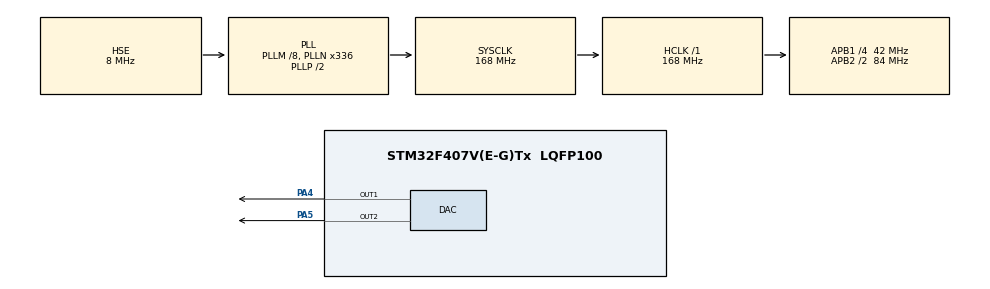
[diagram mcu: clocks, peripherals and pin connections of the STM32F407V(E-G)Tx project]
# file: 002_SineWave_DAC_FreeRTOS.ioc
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DAC.DAC_Trigger=DAC_TRIGGER_T6_TRGO
DAC.DAC_Trigger2=DAC_TRIGGER_T6_TRGO
Dma.DAC1.0.Direction=DMA_MEMORY_TO_PERIPH
Dma.DAC1.0.FIFOMode=DMA_FIFOMODE_DISABLE
Dma.DAC1.0.Instance=DMA1_Stream5
Dma.DAC1.0.MemDataAlignment=DMA_MDATAALIGN_HALFWORD
Dma.DAC1.0.MemInc=DMA_MINC_ENABLE
Dma.DAC1.0.Mode=DMA_CIRCULAR
Dma.DAC1.0.PeriphDataAlignment=DMA_PDATAALIGN_HALFWORD
Dma.DAC1.0.PeriphInc=DMA_PINC_DISABLE
Dma.DAC1.0.Priority=DMA_PRIORITY_LOW
Dma.DAC2.1.Direction=DMA_MEMORY_TO_PERIPH
Dma.DAC2.1.FIFOMode=DMA_FIFOMODE_DISABLE
Dma.DAC2.1.Instance=DMA1_Stream6
Dma.DAC2.1.MemDataAlignment=DMA_MDATAALIGN_HALFWORD
Dma.DAC2.1.MemInc=DMA_MINC_ENABLE
Dma.DAC2.1.Mode=DMA_CIRCULAR
Dma.DAC2.1.PeriphDataAlignment=DMA_PDATAALIGN_HALFWORD
Dma.DAC2.1.PeriphInc=DMA_PINC_DISABLE
Dma.DAC2.1.Priority=DMA_PRIORITY_LOW
Dma.Request0=DAC1
Dma.Request1=DAC2
FREERTOS.Queues01=sineQueue,16,uint32_t,0,Dynamic,NULL,NULL
FREERTOS.Tasks01=defaultTask,24,128,StartDefaultTask,Default,NULL,Dynamic,NULL,NULL;sineTask,8,256,StartSineTask,Default,NULL,Dynamic,NULL,NULL
FREERTOS.configUSE_NEWLIB_REENTRANT=1
Mcu.Family=STM32F4
Mcu.Name=STM32F407V(E-G)Tx
Mcu.Package=LQFP100
NVIC.DMA1_Stream5_IRQn=true\:5\:0\:false\:false\:true\:true\:false\:true\:true
NVIC.DMA1_Stream6_IRQn=true\:5\:0\:false\:false\:true\:true\:false\:true\:true
NVIC.PriorityGroup=NVIC_PRIORITYGROUP_4
NVIC.TIM6_DAC_IRQn=true\:5\:0\:false\:false\:true\:true\:true\:true\:true
NVIC.TIM8_TRG_COM_TIM14_IRQn=true\:15\:0\:false\:false\:true\:false\:false\:true\:true
NVIC.TimeBase=TIM8_TRG_COM_TIM14_IRQn
NVIC.TimeBaseIP=TIM14
PA13.Mode=Serial_Wire
PA13.Signal=SYS_JTMS-SWDIO
PA14.Mode=Serial_Wire
PA14.Signal=SYS_JTCK-SWCLK
PA4.Signal=COMP_DAC1_group
PA5.Signal=COMP_DAC2_group
PC14-OSC32_IN.Mode=LSE-External-Oscillator
PC14-OSC32_IN.Signal=RCC_OSC32_IN
PC15-OSC32_OUT.Mode=LSE-External-Oscillator
PC15-OSC32_OUT.Signal=RCC_OSC32_OUT
PH0-OSC_IN.Mode=HSE-External-Oscillator
PH0-OSC_IN.Signal=RCC_OSC_IN
PH1-OSC_OUT.Mode=HSE-External-Oscillator
PH1-OSC_OUT.Signal=RCC_OSC_OUT
ProjectManager.HeapSize=0x200
ProjectManager.StackSize=0x400
ProjectManager.TargetToolchain=STM32CubeIDE
RCC.48MHZClocksFreq_Value=48000000
RCC.AHBFreq_Value=168000000
RCC.APB1CLKDivider=RCC_HCLK_DIV4
RCC.APB1Freq_Value=42000000
RCC.APB1TimFreq_Value=84000000
RCC.APB2CLKDivider=RCC_HCLK_DIV2
RCC.APB2Freq_Value=84000000
RCC.APB2TimFreq_Value=168000000
RCC.CortexFreq_Value=168000000
RCC.HCLKFreq_Value=168000000
RCC.HSE_VALUE=8000000
RCC.HSI_VALUE=16000000
RCC.PLLM=8
RCC.PLLN=336
RCC.PLLQ=7
RCC.PLLSourceVirtual=RCC_PLLSOURCE_HSE
RCC.SYSCLKFreq_VALUE=168000000
RCC.SYSCLKSource=RCC_SYSCLKSOURCE_PLLCLK
RCC.VCOOutputFreq_Value=336000000
SH.COMP_DAC1_group.0=DAC_OUT1,DAC_OUT1
SH.COMP_DAC2_group.0=DAC_OUT2,DAC_OUT2
TIM6.Period=10-1
TIM6.Prescaler=84-1
VP_FREERTOS_VS_CMSIS_V2.Mode=CMSIS_V2
VP_SYS_VS_tim14.Mode=TIM14
VP_TIM6_VS_ClockSourceINT.Mode=Enable_Timer
board=STM32F407G-DISC1

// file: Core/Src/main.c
/* USER CODE BEGIN Header */
/**
  ******************************************************************************
  * @file           : main.c
  * @brief          : Main program body
  ******************************************************************************
  * @attention
  *
  * Copyright (c) 2025 STMicroelectronics.
  * All rights reserved.
  *
  * This software is licensed under terms that can be found in the LICENSE file
  * in the root directory of this software component.
  * If no LICENSE file comes with this software, it is provided AS-IS.
  *
  ******************************************************************************
  */
/* USER CODE END Header */
#include "main.h"
#include "cmsis_os.h"

/* USER CODE BEGIN Includes */
#include "arm_math.h"
#include "math.h"
/* USER CODE END Includes */

/* USER CODE BEGIN PTD */
typedef struct{
	uint16_t *buffer;
	float angle;
	float angle_change;
	float amplification;
} sine_queue_t;
/* USER CODE END PTD */

/* USER CODE BEGIN PD */
#define DMA_BUFFER_SIZE 64
#define SAMPLE_FREQ 	100000
#define OUTPUT_MID 		2048
/* USER CODE END PD */

DAC_HandleTypeDef hdac;
DMA_HandleTypeDef hdma_dac1;
DMA_HandleTypeDef hdma_dac2;

TIM_HandleTypeDef htim6;

/* Definitions for defaultTask */
osThreadId_t defaultTaskHandle;
const osThreadAttr_t defaultTask_attributes = {
  .name = "defaultTask",
  .stack_size = 128 * 4,
  .priority = (osPriority_t) osPriorityNormal,
};
/* Definitions for sineTask */
osThreadId_t sineTaskHandle;
const osThreadAttr_t sineTask_attributes = {
  .name = "sineTask",
  .stack_size = 256 * 4,
  .priority = (osPriority_t) osPriorityLow,
};
/* Definitions for sineQueue */
osMessageQueueId_t sineQueueHandle;
const osMessageQueueAttr_t sineQueue_attributes = {
  .name = "sineQueue"
};
/* USER CODE BEGIN PV */
const float two_pi = 2 * M_PI;

uint16_t dma_buffer_1[DMA_BUFFER_SIZE *2];
uint16_t dma_buffer_2[DMA_BUFFER_SIZE *2];

sine_queue_t dac[2] = {
		{
				.buffer = dma_buffer_1,
				.angle = 0,
				.angle_change = 1000*(two_pi/SAMPLE_FREQ),
				.amplification = 0.99
		},
		{
				.buffer = dma_buffer_2,
				.angle = 0,
				.angle_change = 999.9*(two_pi/SAMPLE_FREQ),
				.amplification = 0.8
		}
};

/* USER CODE END PV */

void SystemClock_Config(void);
static void MX_GPIO_Init(void);
static void MX_DMA_Init(void);
static void MX_DAC_Init(void);
static void MX_TIM6_Init(void);
void StartDefaultTask(void *argument);
void StartSineTask(void *argument);

/* USER CODE BEGIN PFP */
void HAL_DAC_ConvCpltCallbackCh1(DAC_HandleTypeDef *hdac);
void HAL_DAC_ConvHalfCpltCallbackCh1(DAC_HandleTypeDef *hdac);
/* USER CODE END PFP */

int main(void)
{

  /* MCU Configuration--------------------------------------------------------*/

  /* Reset of all peripherals, Initializes the Flash interface and the Systick. */
  HAL_Init();

  /* Configure the system clock */
  SystemClock_Config();

  /* Initialize all configured peripherals */
  MX_GPIO_Init();
  MX_DMA_Init();
  MX_DAC_Init();
  MX_TIM6_Init();
  /* USER CODE BEGIN 2 */
  HAL_TIM_Base_Start_IT(&htim6);

  HAL_DAC_Start_DMA(&hdac, DAC1_CHANNEL_1, (uint32_t *)&dma_buffer_1, 2*DMA_BUFFER_SIZE, DAC_ALIGN_12B_R);
  HAL_DAC_Start_DMA(&hdac, DAC1_CHANNEL_2, (uint32_t *)&dma_buffer_2, 2*DMA_BUFFER_SIZE, DAC_ALIGN_12B_R);
  /* USER CODE END 2 */

  /* Init scheduler */
  osKernelInitialize();

  /* Create the queue(s) */
  /* creation of sineQueue */
  sineQueueHandle = osMessageQueueNew (16, sizeof(uint32_t), &sineQueue_attributes);

  /* Create the thread(s) */
  /* creation of defaultTask */
  defaultTaskHandle = osThreadNew(StartDefaultTask, NULL, &defaultTask_attributes);

  /* creation of sineTask */
  sineTaskHandle = osThreadNew(StartSineTask, NULL, &sineTask_attributes);

  /* Start scheduler */
  osKernelStart();

  /* We should never get here as control is now taken by the scheduler */

  /* Infinite loop */
  while (1)
  {

  }
}

void SystemClock_Config(void)
{
  RCC_OscInitTypeDef RCC_OscInitStruct = {0};
  RCC_ClkInitTypeDef RCC_ClkInitStruct = {0};

  /** Configure the main internal regulator output voltage
  */
  __HAL_RCC_PWR_CLK_ENABLE();
  __HAL_PWR_VOLTAGESCALING_CONFIG(PWR_REGULATOR_VOLTAGE_SCALE1);

  /** Initializes the RCC Oscillators according to the specified parameters
  * in the RCC_OscInitTypeDef structure.
  */
  RCC_OscInitStruct.OscillatorType = RCC_OSCILLATORTYPE_HSE;
  RCC_OscInitStruct.HSEState = RCC_HSE_ON;
  RCC_OscInitStruct.PLL.PLLState = RCC_PLL_ON;
  RCC_OscInitStruct.PLL.PLLSource = RCC_PLLSOURCE_HSE;
  RCC_OscInitStruct.PLL.PLLM = 8;
  RCC_OscInitStruct.PLL.PLLN = 336;
  RCC_OscInitStruct.PLL.PLLP = RCC_PLLP_DIV2;
  RCC_OscInitStruct.PLL.PLLQ = 7;
  if (HAL_RCC_OscConfig(&RCC_OscInitStruct) != HAL_OK)
  {
    Error_Handler();
  }

  /** Initializes the CPU, AHB and APB buses clocks
  */
  RCC_ClkInitStruct.ClockType = RCC_CLOCKTYPE_HCLK|RCC_CLOCKTYPE_SYSCLK
                              |RCC_CLOCKTYPE_PCLK1|RCC_CLOCKTYPE_PCLK2;
  RCC_ClkInitStruct.SYSCLKSource = RCC_SYSCLKSOURCE_PLLCLK;
  RCC_ClkInitStruct.AHBCLKDivider = RCC_SYSCLK_DIV1;
  RCC_ClkInitStruct.APB1CLKDivider = RCC_HCLK_DIV4;
  RCC_ClkInitStruct.APB2CLKDivider = RCC_HCLK_DIV2;

  if (HAL_RCC_ClockConfig(&RCC_ClkInitStruct, FLASH_LATENCY_5) != HAL_OK)
  {
    Error_Handler();
  }
}

static void MX_DAC_Init(void)
{

  DAC_ChannelConfTypeDef sConfig = {0};

  /** DAC Initialization
  */
  hdac.Instance = DAC;
  if (HAL_DAC_Init(&hdac) != HAL_OK)
  {
    Error_Handler();
  }

  /** DAC channel OUT1 config
  */
  sConfig.DAC_Trigger = DAC_TRIGGER_T6_TRGO;
  sConfig.DAC_OutputBuffer = DAC_OUTPUTBUFFER_ENABLE;
  if (HAL_DAC_ConfigChannel(&hdac, &sConfig, DAC_CHANNEL_1) != HAL_OK)
  {
    Error_Handler();
  }

  /** DAC channel OUT2 config
  */
  if (HAL_DAC_ConfigChannel(&hdac, &sConfig, DAC_CHANNEL_2) != HAL_OK)
  {
    Error_Handler();
  }

}

static void MX_TIM6_Init(void)
{

  TIM_MasterConfigTypeDef sMasterConfig = {0};

  htim6.Instance = TIM6;
  htim6.Init.Prescaler = 84-1;
  htim6.Init.CounterMode = TIM_COUNTERMODE_UP;
  htim6.Init.Period = 10-1;
  htim6.Init.AutoReloadPreload = TIM_AUTORELOAD_PRELOAD_DISABLE;
  if (HAL_TIM_Base_Init(&htim6) != HAL_OK)
  {
    Error_Handler();
  }
  sMasterConfig.MasterOutputTrigger = TIM_TRGO_RESET;
  sMasterConfig.MasterSlaveMode = TIM_MASTERSLAVEMODE_DISABLE;
  if (HAL_TIMEx_MasterConfigSynchronization(&htim6, &sMasterConfig) != HAL_OK)
  {
    Error_Handler();
  }

}

static void MX_DMA_Init(void)
{

  /* DMA controller clock enable */
  __HAL_RCC_DMA1_CLK_ENABLE();

  /* DMA interrupt init */
  /* DMA1_Stream5_IRQn interrupt configuration */
  HAL_NVIC_SetPriority(DMA1_Stream5_IRQn, 5, 0);
  HAL_NVIC_EnableIRQ(DMA1_Stream5_IRQn);
  /* DMA1_Stream6_IRQn interrupt configuration */
  HAL_NVIC_SetPriority(DMA1_Stream6_IRQn, 5, 0);
  HAL_NVIC_EnableIRQ(DMA1_Stream6_IRQn);

}

static void MX_GPIO_Init(void)
{

  /* GPIO Ports Clock Enable */
  __HAL_RCC_GPIOC_CLK_ENABLE();
  __HAL_RCC_GPIOH_CLK_ENABLE();
  __HAL_RCC_GPIOA_CLK_ENABLE();

}

/* USER CODE BEGIN 4 */
void HAL_DAC_ConvHalfCpltCallbackCh1(DAC_HandleTypeDef *hdac) {
    //++conv_half_ch1;
    dacs[0].buffer = &dma_buffer_1[0];
    uint32_t dac_addr = (uint32_t) &dacs[0];
    osMessageQueuePut(sineQueueHandle, &dac_addr, 0, 0);
}

void HAL_DAC_ConvCpltCallbackCh1(DAC_HandleTypeDef *hdac) {
    //++conv_ch1;
    dacs[0].buffer = &dma_buffer_1[DMA_BUFFER_SIZE];
    uint32_t dac_addr = (uint32_t) &dacs[0];
    osMessageQueuePut(sineQueueHandle, &dac_addr, 0, 0);
}

void HAL_DACEx_ConvHalfCpltCallbackCh2(DAC_HandleTypeDef *hdac) {
    //++conv_half_ch2;
    dacs[1].buffer = &dma_buffer_2[0];
    uint32_t dac_addr = (uint32_t) &dacs[1];
    osMessageQueuePut(sineQueueHandle, &dac_addr, 0, 0);
}

void HAL_DACEx_ConvCpltCallbackCh2(DAC_HandleTypeDef *hdac) {
    //++conv_ch2;
    dacs[1].buffer = &dma_buffer_2[DMA_BUFFER_SIZE];
    uint32_t dac_addr = (uint32_t) &dacs[1];
    osMessageQueuePut(sineQueueHandle, &dac_addr, 0, 0);
}

/* USER CODE END 4 */

void StartDefaultTask(void *argument)
{
  /* USER CODE BEGIN 5 */

	uint32_t loop_cnt = 0;

	    /* Infinite loop */
	for (;;){
		osDelay(100);

		if (loop_cnt % 10 == 0) {
			uint32_t tick = osKernelGetTickCount();
			osMessageQueuePut(tickQueueHandle, &tick, 0, osWaitForever);
		}
		if (loop_cnt % 5 == 0) {
			osSemaphoreRelease(ledSemaphoreHandle);
		}

		++loop_cnt;
	}

  /* USER CODE END 5 */
}

void StartSineTask(void *argument)
{
  /* USER CODE BEGIN StartSineTask */

	osStatus_t ret;

	uint32_t sine_p;

	/* Infinite loop */
	for (;;) {
		ret = osMessageQueueGet(sineQueueHandle, &sine_p, 0, osWaitForever);

		if (ret == osOK) {
			//++sine_task;
			// The message contain a pointer to the relevant sine_queue_t struct
			sine_queue_t *sine = (sine_queue_t*) sine_p;

			// Run through the buffer
			for (int i = 0; i < DMA_BUFFER_SIZE; ++i) {

				// Since we got the angle, calculating the dac value is quite simple.  The arm_cos_f32 function
				// is blindingly fast compared with the fpu
				sine->buffer[i] = OUTPUT_MID - (sine->amplification * (OUTPUT_MID * arm_cos_f32(sine->angle)));

				// Prepare angle for next point simply by adding the pre-calculated angle change (based on frequency)
				sine->angle += sine->angle_change;

				// If we've gone full circle - cycle back
				if (sine->angle >= two_pi) {
					sine->angle -= two_pi;
				}
			}

		}

	}

  /* USER CODE END StartSineTask */
}

void HAL_TIM_PeriodElapsedCallback(TIM_HandleTypeDef *htim)
{
  if (htim->Instance == TIM14)
  {
    HAL_IncTick();
  }
}

void Error_Handler(void)
{
  __disable_irq();
  while (1)
  {
  }
}
